# regs-internal register map
Registers are 32-bit, access not given, no defined reset value unless marked. A register's access mark holds for its fields unless they carry their own. Addresses are absolute; registers are grouped by the start of their names; [hi:lo] are bit positions; {n}, {i} and the like mark numbered series.

## GPIO
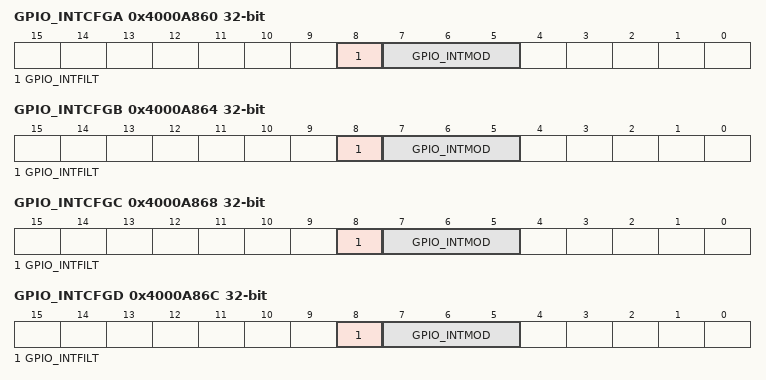
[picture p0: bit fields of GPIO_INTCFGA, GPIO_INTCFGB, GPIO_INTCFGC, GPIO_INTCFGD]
0x4000A860 GPIO_INTCFGA
  [8] GPIO_INTFILT, [7:5] GPIO_INTMOD
0x4000A864 GPIO_INTCFGB
  [8] GPIO_INTFILT, [7:5] GPIO_INTMOD
0x4000A868 GPIO_INTCFGC
  [8] GPIO_INTFILT, [7:5] GPIO_INTMOD
0x4000A86C GPIO_INTCFGD
  [8] GPIO_INTFILT, [7:5] GPIO_INTMOD
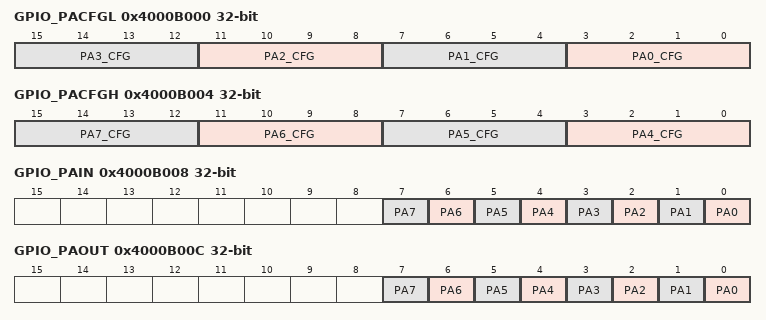
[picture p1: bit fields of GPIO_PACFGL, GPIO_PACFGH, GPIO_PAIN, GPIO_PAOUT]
0x4000B000 GPIO_PACFGL
  [4n+3:4n] PA{n}_CFG (n=0..3)
0x4000B004 GPIO_PACFGH
  [4n-13:4n-16] PA{n}_CFG (n=4..7)
0x4000B008 GPIO_PAIN
  [n] PA{n} (n=0..7)
0x4000B00C GPIO_PAOUT
  [n] PA{n} (n=0..7)
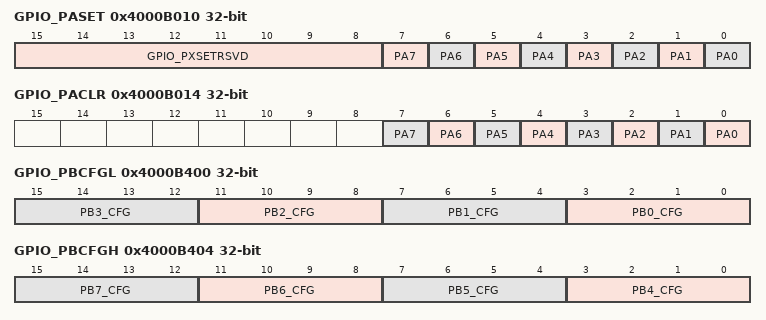
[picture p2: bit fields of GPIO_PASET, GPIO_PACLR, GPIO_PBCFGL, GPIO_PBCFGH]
0x4000B010 GPIO_PASET
  [15:8] GPIO_PXSETRSVD, [n] PA{n} (n=0..7)
0x4000B014 GPIO_PACLR
  [n] PA{n} (n=0..7)
0x4000B400 GPIO_PBCFGL
  [4n+3:4n] PB{n}_CFG (n=0..3)
0x4000B404 GPIO_PBCFGH
  [4n-13:4n-16] PB{n}_CFG (n=4..7)
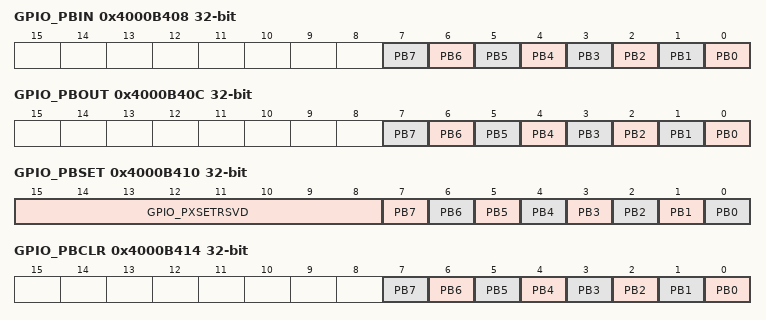
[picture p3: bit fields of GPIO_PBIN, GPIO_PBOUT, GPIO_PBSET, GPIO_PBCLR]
0x4000B408 GPIO_PBIN
  [n] PB{n} (n=0..7)
0x4000B40C GPIO_PBOUT
  [n] PB{n} (n=0..7)
0x4000B410 GPIO_PBSET
  [15:8] GPIO_PXSETRSVD, [n] PB{n} (n=0..7)
0x4000B414 GPIO_PBCLR
  [n] PB{n} (n=0..7)
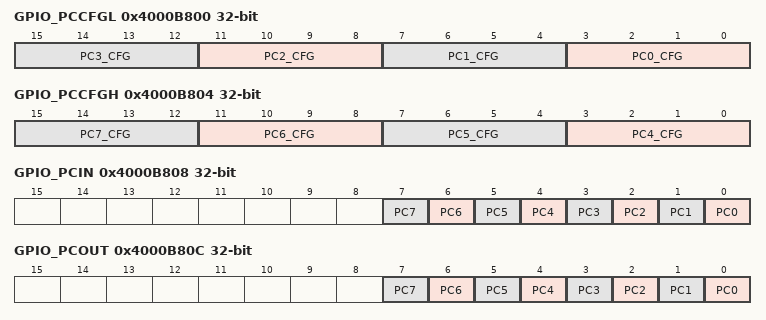
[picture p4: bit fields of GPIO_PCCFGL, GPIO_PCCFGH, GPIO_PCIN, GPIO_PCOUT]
0x4000B800 GPIO_PCCFGL
  [4n+3:4n] PC{n}_CFG (n=0..3)
0x4000B804 GPIO_PCCFGH
  [4n-13:4n-16] PC{n}_CFG (n=4..7)
0x4000B808 GPIO_PCIN
  [n] PC{n} (n=0..7)
0x4000B80C GPIO_PCOUT
  [n] PC{n} (n=0..7)
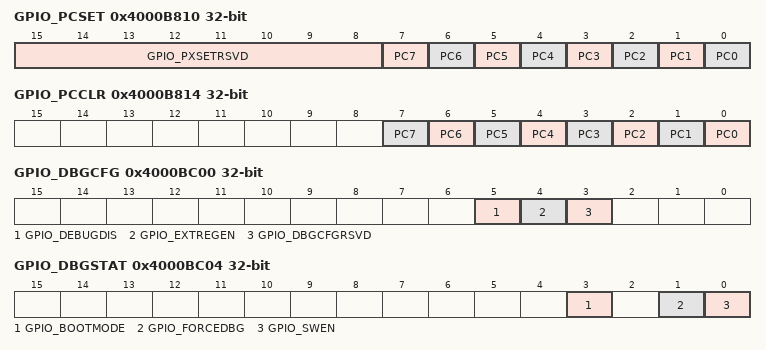
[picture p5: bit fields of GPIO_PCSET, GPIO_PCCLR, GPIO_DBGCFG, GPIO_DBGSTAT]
0x4000B810 GPIO_PCSET
  [15:8] GPIO_PXSETRSVD, [n] PC{n} (n=0..7)
0x4000B814 GPIO_PCCLR
  [n] PC{n} (n=0..7)
0x4000BC00 GPIO_DBGCFG
  [5] GPIO_DEBUGDIS, [4] GPIO_EXTREGEN, [3] GPIO_DBGCFGRSVD
0x4000BC04 GPIO_DBGSTAT
  [3] GPIO_BOOTMODE, [1] GPIO_FORCEDBG, [0] GPIO_SWEN
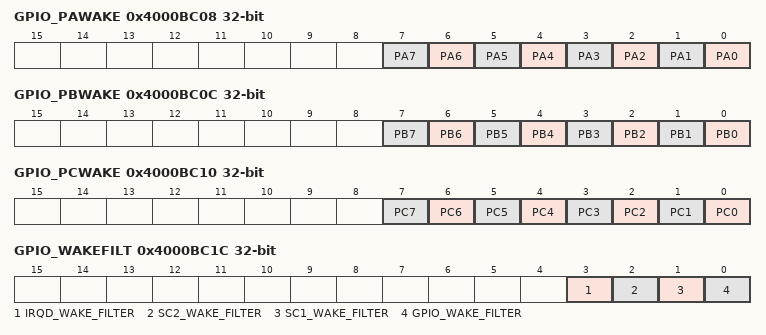
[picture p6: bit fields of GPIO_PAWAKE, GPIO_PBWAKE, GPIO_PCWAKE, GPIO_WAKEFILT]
0x4000BC08 GPIO_PAWAKE
  [n] PA{n} (n=0..7)
0x4000BC0C GPIO_PBWAKE
  [n] PB{n} (n=0..7)
0x4000BC10 GPIO_PCWAKE
  [n] PC{n} (n=0..7)
0x4000BC14 GPIO_IRQCSEL
  [4:0] SEL_GPIO
0x4000BC18 GPIO_IRQDSEL
  [4:0] SEL_GPIO
0x4000BC1C GPIO_WAKEFILT
  [3] IRQD_WAKE_FILTER, [2] SC2_WAKE_FILTER, [1] SC1_WAKE_FILTER, [0] GPIO_WAKE_FILTER

## TIM1
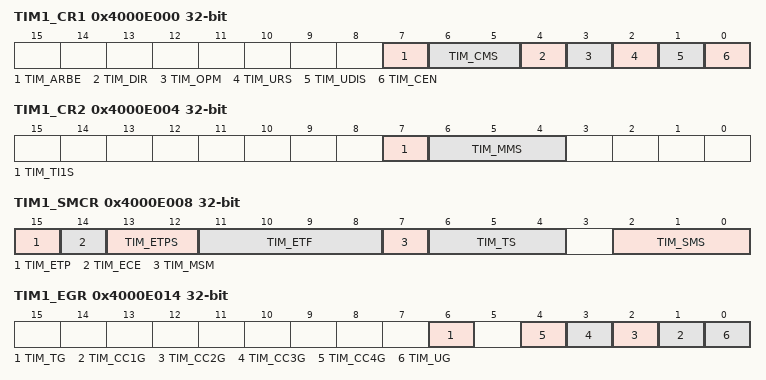
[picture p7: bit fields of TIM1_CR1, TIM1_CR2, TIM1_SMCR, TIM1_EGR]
0x4000E000 TIM1_CR1
  [7] TIM_ARBE, [6:5] TIM_CMS, [4] TIM_DIR, [3] TIM_OPM, [2] TIM_URS, [1] TIM_UDIS, [0] TIM_CEN
0x4000E004 TIM1_CR2
  [7] TIM_TI1S, [6:4] TIM_MMS
0x4000E008 TIM1_SMCR
  [15] TIM_ETP, [14] TIM_ECE, [13:12] TIM_ETPS, [11:8] TIM_ETF, [7] TIM_MSM, [6:4] TIM_TS, [2:0] TIM_SMS
0x4000E014 TIM1_EGR
  [6] TIM_TG, [n] TIM_CC{n}G (n=1..4), [0] TIM_UG
0x4000E018 TIM1_CCMR1
  [15] TIM_OC2CE, [15:12] TIM_IC2F, [14:12] TIM_OC2M, [11] TIM_OC2BE, [11:10] TIM_IC2PSC, [10] TIM_OC2FE, [9:8] TIM_CC2S, [7] TIM_OC1CE, [7:4] TIM_IC1F, [6:4] TIM_OC1M, [3] TIM_OC1PE, [3:2] TIM_IC1PSC, [2] TIM_OC1FE, [1:0] TIM_CC1S
0x4000E01C TIM1_CCMR2
  [15] TIM_OC4CE, [15:12] TIM_IC4F, [14:12] TIM_OC4M, [11] TIM_OC4BE, [11:10] TIM_IC4PSC, [10] TIM_OC4FE, [9:8] TIM_CC4S, [7] TIM_OC3CE, [7:4] TIM_IC3F, [6:4] TIM_OC3M, [3] TIM_OC3BE, [3:2] TIM_IC3PSC, [2] TIM_OC3FE, [1:0] TIM_CC3S
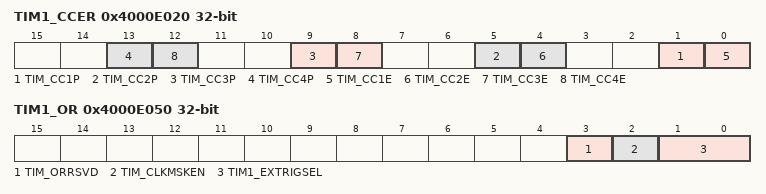
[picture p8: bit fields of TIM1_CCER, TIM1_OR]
0x4000E020 TIM1_CCER
  [4n-3] TIM_CC{n}P (n=1..4), [4n-4] TIM_CC{n}E (n=1..4)
0x4000E024 TIM1_CNT
  [15:0] TIM_CNT
0x4000E028 TIM1_PSC
  [3:0] TIM_PSC
0x4000E02C TIM1_ARR
  [15:0] TIM_ARR
{0x4000E030+4i} TIM1_CCR{i} (i=1..4)
  [15:0] TIM_CCR
0x4000E050 TIM1_OR
  [3] TIM_ORRSVD, [2] TIM_CLKMSKEN, [1:0] TIM1_EXTRIGSEL

## TMR1
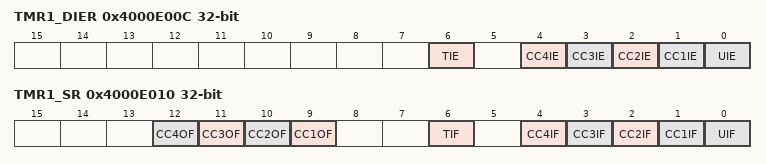
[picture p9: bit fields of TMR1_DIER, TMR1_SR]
0x4000E00C TMR1_DIER
  [6] TIE, [n] CC{n}IE (n=1..4), [0] UIE
0x4000E010 TMR1_SR
  [n+8] CC{n}OF (n=1..4), [6] TIF, [n] CC{n}IF (n=1..4), [0] UIF

## TIM2
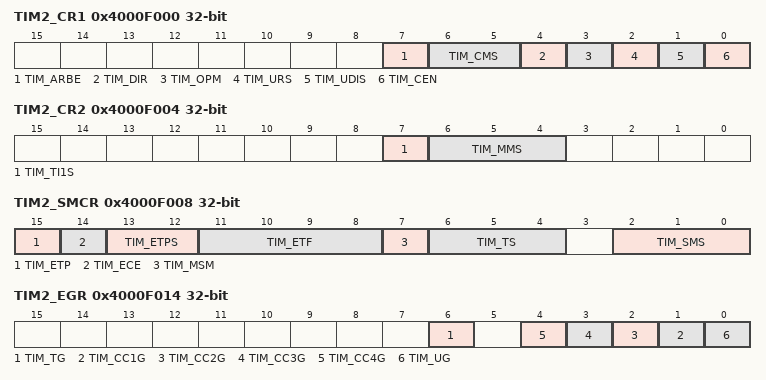
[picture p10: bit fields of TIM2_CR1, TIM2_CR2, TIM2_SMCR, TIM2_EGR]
0x4000F000 TIM2_CR1
  [7] TIM_ARBE, [6:5] TIM_CMS, [4] TIM_DIR, [3] TIM_OPM, [2] TIM_URS, [1] TIM_UDIS, [0] TIM_CEN
0x4000F004 TIM2_CR2
  [7] TIM_TI1S, [6:4] TIM_MMS
0x4000F008 TIM2_SMCR
  [15] TIM_ETP, [14] TIM_ECE, [13:12] TIM_ETPS, [11:8] TIM_ETF, [7] TIM_MSM, [6:4] TIM_TS, [2:0] TIM_SMS
0x4000F014 TIM2_EGR
  [6] TIM_TG, [n] TIM_CC{n}G (n=1..4), [0] TIM_UG
0x4000F018 TIM2_CCMR1
  [15] TIM_OC2CE, [15:12] TIM_IC2F, [14:12] TIM_OC2M, [11] TIM_OC2BE, [11:10] TIM_IC2PSC, [10] TIM_OC2FE, [9:8] TIM_CC2S, [7] TIM_OC1CE, [7:4] TIM_IC1F, [6:4] TIM_OC1M, [3] TIM_OC1PE, [3:2] TIM_IC1PSC, [2] TIM_OC1FE, [1:0] TIM_CC1S
0x4000F01C TIM2_CCMR2
  [15] TIM_OC4CE, [15:12] TIM_IC4F, [14:12] TIM_OC4M, [11] TIM_OC4BE, [11:10] TIM_IC4PSC, [10] TIM_OC4FE, [9:8] TIM_CC4S, [7] TIM_OC3CE, [7:4] TIM_IC3F, [6:4] TIM_OC3M, [3] TIM_OC3BE, [3:2] TIM_IC3PSC, [2] TIM_OC3FE, [1:0] TIM_CC3S
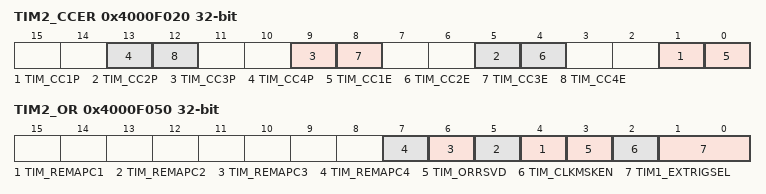
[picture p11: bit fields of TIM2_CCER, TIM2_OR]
0x4000F020 TIM2_CCER
  [4n-3] TIM_CC{n}P (n=1..4), [4n-4] TIM_CC{n}E (n=1..4)
0x4000F024 TIM2_CNT
  [15:0] TIM_CNT
0x4000F028 TIM2_PSC
  [3:0] TIM_PSC
0x4000F02C TIM2_ARR
  [15:0] TIM_ARR
{0x4000F030+4i} TIM2_CCR{i} (i=1..4)
  [15:0] TIM_CCR
0x4000F050 TIM2_OR
  [n+3] TIM_REMAPC{n} (n=1..4), [3] TIM_ORRSVD, [2] TIM_CLKMSKEN, [1:0] TIM1_EXTRIGSEL
